# GD32E51x_CL register map
File version: 1.0
CPU: CM33 r0p4, little endian, MPU, FPU, 4 interrupt priority bits
Registers are 32-bit, read-write, reset 0x0 unless marked. A register's access mark holds for its fields unless they carry their own. Offsets are from the block's base; [hi:lo] are bit positions.

## TIMER14 — General level3 timer
Base 0x40014000
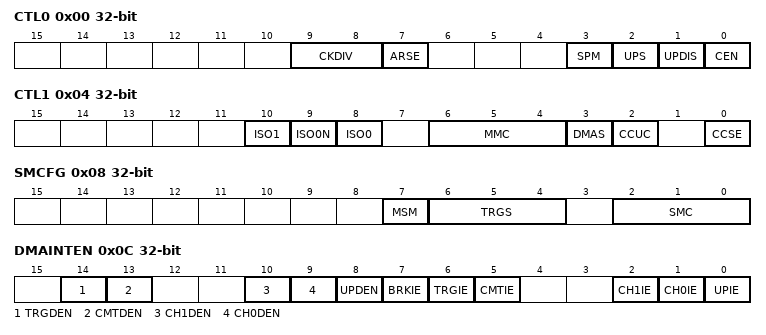
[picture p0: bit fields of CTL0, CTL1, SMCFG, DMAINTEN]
0x00 CTL0 — Control register 0
  [9:8] CKDIV — Clock division
  [7] ARSE — Auto-reload shadow enable
  [3] SPM — Single pulse mode.
  [2] UPS — Update source
  [1] UPDIS — Update disable.
  [0] CEN — Counter enable
0x04 CTL1 — Control register 1
  [10] ISO1 — Idle state of channel 1 output
  [9] ISO0N — Idle state of channel 0 complementary output
  [8] ISO0 — Idle state of channel 0 output
  [6:4] MMC — Master mode control
  [3] DMAS — DMA request source selection
  [2] CCUC — Commutation control shadow register update control
  [0] CCSE — Commutation control shadow enable
0x08 SMCFG — Slave mode configuration register
  [7] MSM — Master-slave mode
  [6:4] TRGS — Trigger selection
  [2:0] SMC — Slave mode control
0x0C DMAINTEN — DMA and interrupt enable register
  [14] TRGDEN — Trigger DMA request enable
  [13] CMTDEN — Commutation DMA request enable
  [10] CH1DEN — Channel 1 capture/compare DMA request enable
  [9] CH0DEN — Channel 0 capture/compare DMA request enable
  [8] UPDEN — Update DMA request enable
  [7] BRKIE — Break interrupt enable
  [6] TRGIE — Trigger interrupt enable
  [5] CMTIE — commutation interrupt enable
  [2] CH1IE — Channel 1 capture/compare interrupt enable
  [1] CH0IE — Channel 0 capture/compare interrupt enable
  [0] UPIE — Update interrupt enable
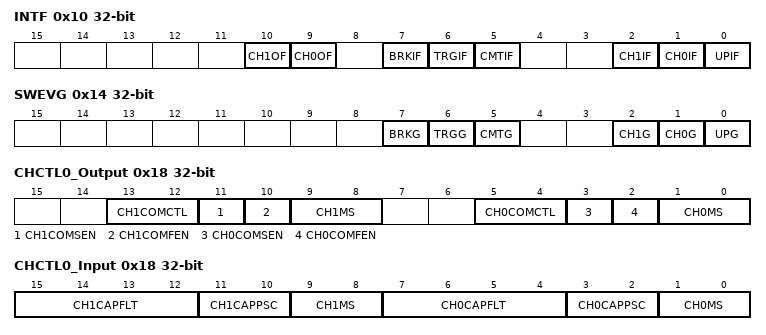
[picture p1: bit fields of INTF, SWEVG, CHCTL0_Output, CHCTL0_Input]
0x10 INTF — Interrupt flag register
  [10] CH1OF — Channel 1 over capture flag
  [9] CH0OF — Channel 0 over capture flag
  [7] BRKIF — Break interrupt flag
  [6] TRGIF — Trigger interrupt flag
  [5] CMTIF — Channel commutation interrupt flag
  [2] CH1IF — Channel 1 s capture/compare interrupt flag
  [1] CH0IF — Channel 0 s capture/compare interrupt flag
  [0] UPIF — Update interrupt flag
0x14 SWEVG wo — Software event generation register
  [7] BRKG — Break event generation
  [6] TRGG — Trigger event generation
  [5] CMTG — Channel commutation event generation
  [2] CH1G — Channel 1 s capture or compare event generation
  [1] CH0G — Channel 0 s capture or compare event generation
  [0] UPG — Update event generation
0x18 CHCTL0_Output — Channel control register 0 (output mode)
  [13:12] CH1COMCTL — Channel 1 compare output control
  [11] CH1COMSEN — Channel 1 output compare shadow enable
  [10] CH1COMFEN — Channel 1 output compare fast enable
  [9:8] CH1MS — Channel 1 mode selection
  [5:4] CH0COMCTL — Channel 0 compare output control
  [3] CH0COMSEN — Channel 0 compare output shadow enable
  [2] CH0COMFEN — Channel 0 output compare fast enable
  [1:0] CH0MS — Channel 0 I/O mode selection
0x18 CHCTL0_Input (alternate view of CHCTL0_Output) — Channel control register 0 ( (input mode)
  [15:12] CH1CAPFLT — Channel 1 input capture filter control
  [11:10] CH1CAPPSC — Channel 1 input capture prescaler
  [9:8] CH1MS — Channel 1 mode selection
  [7:4] CH0CAPFLT — Channel 0 input capture filter control
  [3:2] CH0CAPPSC — Channel 0 input capture prescaler
  [1:0] CH0MS — Channel 0 mode selection
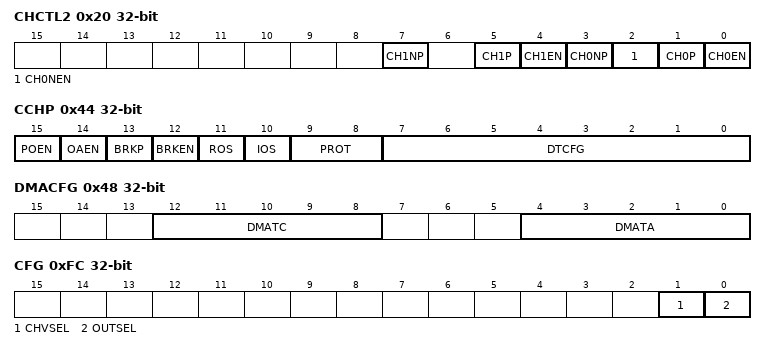
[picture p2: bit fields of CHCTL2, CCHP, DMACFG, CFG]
0x20 CHCTL2 — Channel control register 2
  [7] CH1NP — Channel 1 complementary output polarity
  [5] CH1P — Channel 1 capture/compare function polarity
  [4] CH1EN — Channel 1 capture/compare function enable
  [3] CH0NP — Channel 0 complementary output polarity
  [2] CH0NEN — Channel 0 complementary output enable
  [1] CH0P — Channel 0 capture/compare function polarity
  [0] CH0EN — Channel 0 capture/compare function enable
0x24 CNT — Counter register
  [15:0] CNT — This bit-filed indicates the current counter value. Writing to this bit-filed can change the value of the counter.
0x28 PSC — Prescaler register
  [15:0] PSC — Prescaler value of the counter clock
0x2C CAR — Counter auto reload register
  [15:0] CARL — Counter auto reload value
0x30 CREP — Counter repetition register
  [7:0] CREP — Counter repetition value
0x34 CH0CV — Channel 0 capture/compare value register
  [15:0] CH0VAL — Capture or compare value of channel0
0x38 CH1CV — Channel 1 capture/compare value register
  [15:0] CH1VAL — Capture or compare value of channel1
0x44 CCHP — Complementary channel protection register
  [15] POEN — Primary output enable
  [14] OAEN — Output automatic enable
  [13] BRKP — Break polarity
  [12] BRKEN — Break enable
  [11] ROS — Run mode off-state enable
  [10] IOS — Idle mode off-state enable
  [9:8] PROT — Complementary register protect control
  [7:0] DTCFG — Dead time configure
0x48 DMACFG — DMA configuration register
  [12:8] DMATC — DMA transfer count
  [4:0] DMATA — DMA transfer access start address
0x4C DMATB — DMA transfer buffer register
  [15:0] DMATB — DMA transfer buffer
0xFC CFG — Configuration register
  [1] CHVSEL — Write CHxVAL register selection
  [0] OUTSEL — The output value selection
